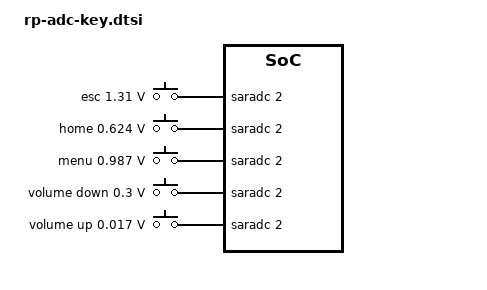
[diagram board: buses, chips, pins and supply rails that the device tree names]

/ {
	adc-keys {
		compatible = "adc-keys";
		io-channels = <&saradc 2>;
		io-channel-names = "buttons";
		poll-interval = <100>;
		keyup-threshold-microvolt = <1800000>;

		esc-key {
			linux,code = <KEY_ESC>;
			label = "esc";
			press-threshold-microvolt = <1310000>;
		};

		home-key {
			linux,code = <KEY_HOME>;
			label = "home";
			press-threshold-microvolt = <624000>;
		};

		menu-key {
			linux,code = <KEY_MENU>;
			label = "menu";
			press-threshold-microvolt = <987000>;
		};

		vol-down-key {
			linux,code = <KEY_VOLUMEDOWN>;
			label = "volume down";
			press-threshold-microvolt = <300000>;
		};

		vol-up-key {
			linux,code = <KEY_VOLUMEUP>;
			label = "volume up";
			press-threshold-microvolt = <17000>;
		};
	};
};
